# ARMv8M-Baseline register map
Registers are read-only, no defined reset value unless marked. A register's access mark holds for its fields unless they carry their own. Offsets are from the block's base; lines under a group give offsets from that group; [hi:lo] are bit positions; {n}, {i} and the like mark numbered series; 'fields as' and 'values as' point back to an identical list; <NAME> marks a mode.

## Memory map
0xE0000000 ITM size 0x1000 — Instrumentation Macrocell
0xE0001000 DWT size 0x1000 — Data Watchpoint and Trace
0xE0002000 FPB size 0x1000 — Flash Patch and Breakpoint
0xE000E004 ICB size 0xC — Implementation Control Block
0xE000E010 SYSTICK size 0x20 — SysTick Timer
0xE000E100 NVIC size 0x380 — Nested Vectored Interrupt Controller
0xE000ED00 SCB size 0x90 — System Control Block
0xE000ED90 MPU size 0x40 — Memory Protection Unit
0xE000EDD0 SAU size 0x1C — Security Attribution Unit
0xE000EDF0 DCB size 0x1C — Debug Control Block
0xE000EF00 SIG size 0x4 — Software Interrupt Generation
0xE000EF34 FP size 0x18 — Floating-Point Extension
0xE000EF50 CMO size 0x2C — Cache Maintenance Operations
0xE000EFB0 DIB size 0x50 — Debug Identification Block

## CMO — Cache Maintenance Operations
Base 0xE000EF50
0x00 ICIALLU wo — Instruction Cache Invalidate All to PoU invalidate all instruction caches to PoU
  [31:0] Ignored — The value written to this field is ignored. Ignored
0x08 ICIMVAU wo — Instruction Cache line Invalidate by Address to PoU invalidate instruction cache line by address to PoU
  [31:0] ADDRESS — Address. Writing to this field initiates the maintenance operation for the address written
0x0C DCIMVAC wo — Data Cache line Invalidate by Address to PoC invalidate data or unified cache line by address to PoC
  fields as ICIMVAU
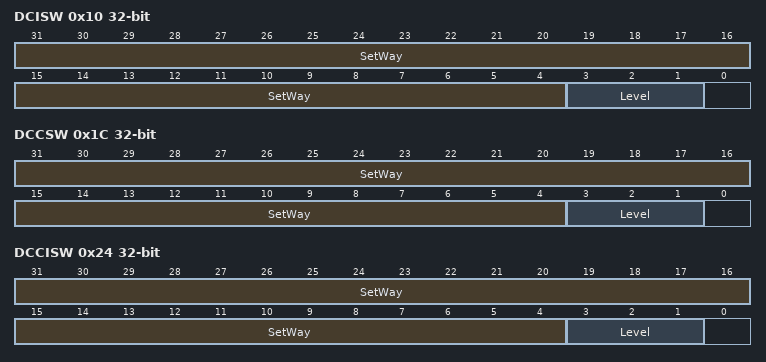
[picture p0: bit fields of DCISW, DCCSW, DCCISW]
0x10 DCISW wo — Data Cache line Invalidate by Set/Way invalidate data or unified cache line by set/way
  [31:4] SetWay — Cache set/way. Contains two fields: Way, bits[31:32-A], the number of the way to operate on
  [3:1] Level — Cache level. Cache level to operate on, minus 1
0x14 DCCMVAU wo — Data Cache line Clean by address to PoU clean data or unified cache line by address to PoU
  fields as ICIMVAU
0x18 DCCMVAC wo — Data Cache line Clean by Address to PoC clean data or unified cache line by address to PoC
  fields as ICIMVAU
0x1C DCCSW wo — Data Cache Clean line by Set/Way clean data or unified cache line by set/way
  [31:4] SetWay — Cache set/way. Contains two fields: Way, bits [31:32-A], the number of the way to operate on
  [3:1] Level — Cache level. Cache level to operate on, minus 1
0x20 DCCIMVAC wo — Data Cache line Clean and Invalidate by Address to PoC clean and invalidate data or unified cache line by address to PoC
  fields as ICIMVAU
0x24 DCCISW wo — Data Cache line Clean and Invalidate by Set/Way clean and invalidate data or unified cache line by set/way
  fields as DCISW
0x28 BPIALL wo — Branch Predictor Invalidate All invalidate all entries from branch predictors
  [31:0] Ignored — Ignored. The value written to this field is ignored

## ICB — Implementation Control Block
Base 0xE000E004
0x00 ICTR — Interrupt Controller Type Register provides information about the interrupt controller
  [3:0] INTLINESNUM — Interrupt line set number
0x04 ACTLR rw — Auxiliary Control Register provides IMPLEMENTATION DEFINED configuration and control options
  [31:0] IMPLEMENTATION DEFINED — IMPLEMENTATION DEFINED. The contents of this field are IMPLEMENTATION DEFINED
0x08 CPPWR rw — Coprocessor Power Control Register specifies whether coprocessors are permitted to enter a non-retentive power state
  [23] SUS11 — State UNKNOWN Secure only 11. The value in this field is ignored
  [22] SU11 — State UNKNOWN 11. The value in this field is ignored
  [21] SUS10 — State UNKNOWN Secure only 10
    0=The SU10 field is accessible from both Security states; 1=The SU10 field is only accessible from the Secure state
  [20] SU10 — State UNKNOWN 10
    0=The floating-point state is not permitted to become UNKNOWN; 1=The floating-point state is permitted to become UNKNOWN
  [0] SUSm — State UNKNOWN Secure only m
    0=The SUm field is accessible from both Security states; 1=The SUm field is only accessible from the Secure state
  [0] SUm — State UNKNOWN m
    0=The coprocessor state is not permitted to become UNKNOWN; 1=The coprocessor state is permitted to become UNKNOWN
